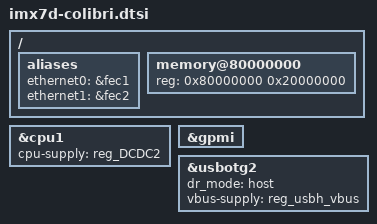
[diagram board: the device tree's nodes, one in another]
#include "imx7d.dtsi"
#include "imx7-colibri.dtsi"
/ {
	aliases {
		ethernet0 = &fec1;
		ethernet1 = &fec2;
	};
	memory@80000000 {
		device_type = "memory";
		reg = <0x80000000 0x20000000>;
	};
};
&cpu1 {
	cpu-supply = <&reg_DCDC2>;
};
&gpmi {
	status = "okay";
};
&usbotg2 {
	dr_mode = "host";
	vbus-supply = <&reg_usbh_vbus>;
};
